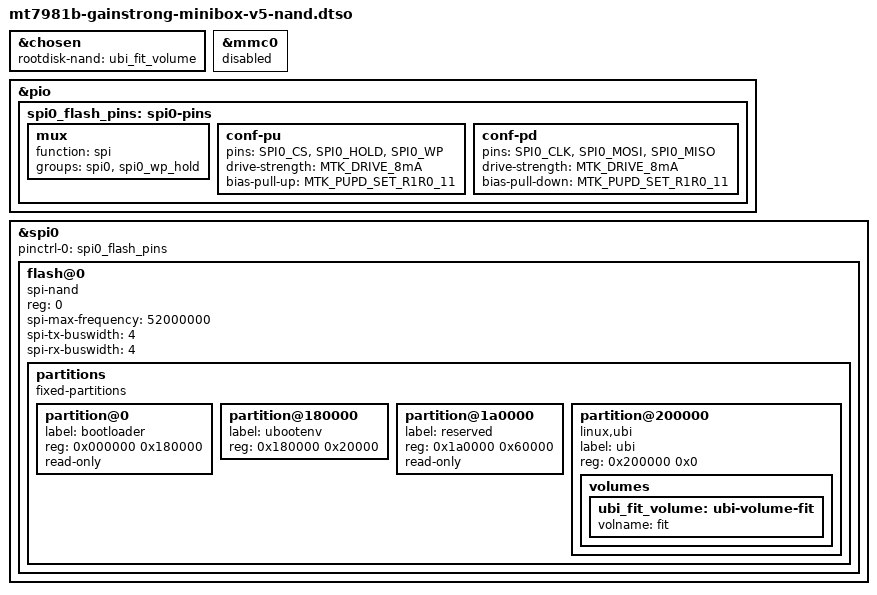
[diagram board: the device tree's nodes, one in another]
/* SPDX-License-Identifier: (GPL-2.0-only OR MIT) */
/dts-v1/;
/plugin/;

#include <dt-bindings/pinctrl/mt65xx.h>

&chosen {
	rootdisk-nand = <&ubi_fit_volume>;
};

&mmc0 {
	status = "disabled";
};

&pio {
	spi0_flash_pins: spi0-pins {
		mux {
			function = "spi";
			groups = "spi0", "spi0_wp_hold";
		};

		conf-pu {
			pins = "SPI0_CS", "SPI0_HOLD", "SPI0_WP";
			drive-strength = <MTK_DRIVE_8mA>;
			bias-pull-up = <MTK_PUPD_SET_R1R0_11>;
		};

		conf-pd {
			pins = "SPI0_CLK", "SPI0_MOSI", "SPI0_MISO";
			drive-strength = <MTK_DRIVE_8mA>;
			bias-pull-down = <MTK_PUPD_SET_R1R0_11>;
		};
	};
};

&spi0 {
	pinctrl-names = "default";
	pinctrl-0 = <&spi0_flash_pins>;
	#address-cells = <1>;
	#size-cells = <0>;
	status = "okay";

	flash@0 {
		compatible = "spi-nand";
		reg = <0>;
		spi-max-frequency = <52000000>;
		spi-tx-buswidth = <4>;
		spi-rx-buswidth = <4>;

		partitions {
			compatible = "fixed-partitions";
			#address-cells = <1>;
			#size-cells = <1>;

			partition@0 {
				label = "bootloader";
				reg = <0x000000 0x180000>;
				read-only;
			};

			partition@180000 {
				label = "ubootenv";
				reg = <0x180000 0x20000>;
			};

			partition@1a0000 {
				label = "reserved";
				reg = <0x1a0000 0x60000>;
				read-only;
			};

			partition@200000 {
				label = "ubi";
				reg = <0x200000 0x0>;
				compatible = "linux,ubi";

				volumes {
					ubi_fit_volume: ubi-volume-fit {
						volname = "fit";
					};
				};
			};
		};
	};
};
